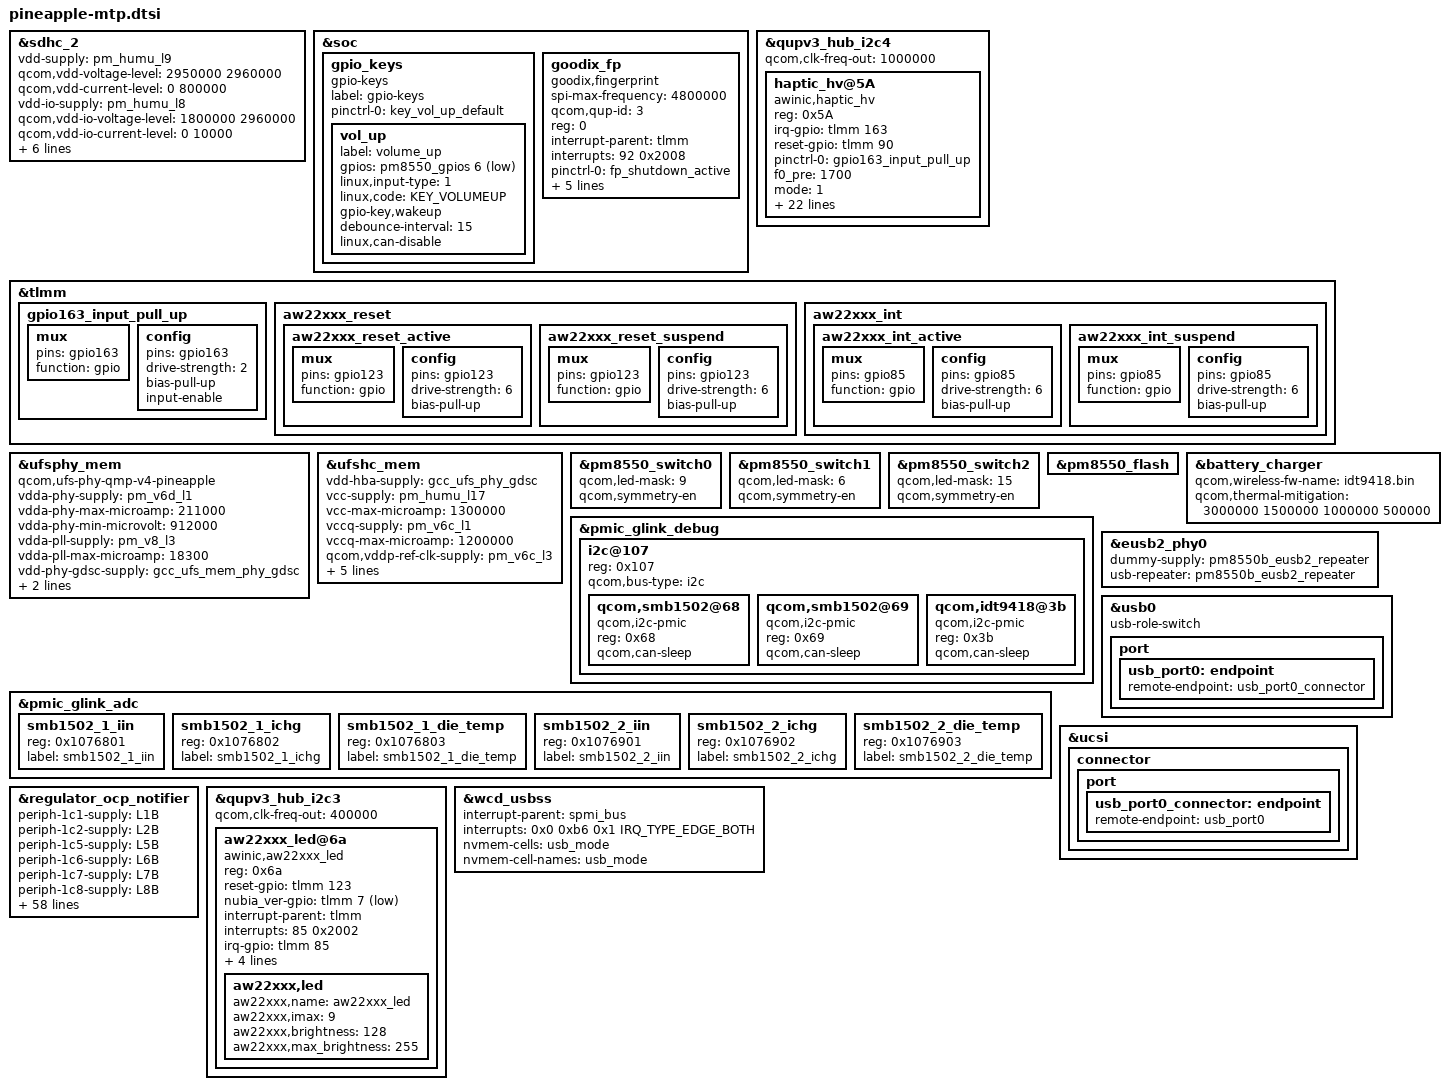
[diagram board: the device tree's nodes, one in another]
#include <dt-bindings/gpio/gpio.h>
#include <dt-bindings/input/input.h>
#include <dt-bindings/clock/qcom,gcc-pineapple.h>
#include "pineapple-pmic-overlay.dtsi"
#include "pineapple-thermal-overlay.dtsi"

&sdhc_2 {
	status = "ok";
	vdd-supply = <&pm_humu_l9>;
	qcom,vdd-voltage-level = <2950000 2960000>;
	qcom,vdd-current-level = <0 800000>;

	vdd-io-supply = <&pm_humu_l8>;
	qcom,vdd-io-voltage-level = <1800000 2960000>;
	qcom,vdd-io-current-level = <0 10000>;

	pinctrl-names = "default", "sleep";
	pinctrl-0 = <&sdc2_on>, <&sd_card_det_default>;
	pinctrl-1 = <&sdc2_off>, <&sd_card_det_default>;

	cd-gpios = <&pm8550_gpios 12 GPIO_ACTIVE_LOW>;

	resets = <&gcc GCC_SDCC2_BCR>;
	reset-names = "core_reset";

	qcom,iommu-dma = "fastmap";
	qcom,uses_level_shifter;
};

&soc {
	gpio_keys {
		compatible = "gpio-keys";
		label = "gpio-keys";

		pinctrl-names = "default";
		pinctrl-0 = <&key_vol_up_default>;

		vol_up {
			label = "volume_up";
			gpios = <&pm8550_gpios 6 GPIO_ACTIVE_LOW>;
			linux,input-type = <1>;
			linux,code = <KEY_VOLUMEUP>;
			gpio-key,wakeup;
			debounce-interval = <15>;
			linux,can-disable;
		};
	};

	goodix_fp {
		status = "ok";
		compatible = "goodix,fingerprint";
		spi-max-frequency = <4800000>;
		qcom,qup-id = <3>;
		reg = <0>;

		interrupt-parent = <&tlmm>;
		interrupts = <92 0x2008>;
		pinctrl-names = "goodix_active", "goodix_suspend", "pwr_active";
		pinctrl-0 = <&fp_shutdown_active>;
		pinctrl-1 = <&fp_shutdown_suspend>;
		pinctrl-2 = <&goodix_pwr_active>;

		fp-gpio-reset = <&tlmm 89 0x0>;
		fp-gpio-irq = <&tlmm 92 0x2008>;
		goodix,gpio_pwr = <&tlmm 93 0x1>;
		interrupt-names = "goodix_wake_up";
	};
};

/* add zte haptic start */
&qupv3_hub_i2c4 {
	status = "ok";
	qcom,clk-freq-out = <1000000>;
	haptic_hv@5A {
		compatible = "awinic,haptic_hv";
		reg = <0x5A>;
		irq-gpio = <&tlmm 163 0>;
		reset-gpio = <&tlmm 90 0>;
		pinctrl-names = "irq_active";
		pinctrl-0 = <&gpio163_input_pull_up>;
		f0_pre = < 1700 >;
		mode = /bits/ 8 < 1 >;
		f0_cali_percent = /bits/ 8 < 7 >;
/******************************aw8692x*******************************/
		aw8692x_max_bst_vol = /bits/ 8 < 0x7F >;
		aw8692x_cont_drv1_lvl = /bits/ 8 < 0x7F >;
		aw8692x_cont_drv2_lvl = /bits/ 8 < 0x50 >;
		aw8692x_cont_drv1_time = /bits/ 8 < 0x04 >;
		aw8692x_cont_drv2_time = /bits/ 8 < 0x06 >;
		aw8692x_cont_drv_width = /bits/ 8 < 0x6A >;
		aw8692x_cont_wait_num = /bits/ 8 < 0x06 >;
		aw8692x_cont_brk_time = /bits/ 8 < 0 >;
		aw8692x_cont_track_margin = /bits/ 8 < 0x0C >;
		aw8692x_brk_bst_md = /bits/ 8 < 0 >;
		aw8692x_cont_tset = /bits/ 8 < 0x06 >;
		aw8692x_cont_bemf_set = /bits/ 8 < 0x02 >;
		aw8692x_cont_bst_brk_gain = /bits/ 8 < 0x05 >;
		aw8692x_cont_brk_gain = /bits/ 8 < 0x08 >;
		aw8692x_duration_time = /bits/ 8 < 20 30 60 >;
		aw8692x_d2s_gain = /bits/ 8 < 0x04 >;
		aw8692x_trig_config = /bits/ 8 < 0 0 0 1 0 2 0 0
						 0 0 0 1 0 2 0 0
						 0 0 0 1 0 2 0 0 >;
		aw8692x_bst_vol_default = /bits/ 8 < 0x50 >;
		aw8692x_bst_vol_ram = /bits/ 8 < 0x50 >;
		aw8692x_bst_vol_rtp = /bits/ 8 < 0x50 >;
		/* aw8692x_is_enabled_auto_bst; */
		/* aw8692x_is_enabled_one_wire; */
	};
};
&tlmm {
	gpio163_input_pull_up: gpio163_input_pull_up {
		mux {
			 pins = "gpio163";
			 function = "gpio";
		};

		config {
			pins = "gpio163";
			drive-strength = <2>;
			bias-pull-up;
			input-enable;
		};
	};
};

&ufsphy_mem {
	compatible = "qcom,ufs-phy-qmp-v4-pineapple";

	/* VDDA_UFS_CORE */
	vdda-phy-supply = <&pm_v6d_l1>;
	vdda-phy-max-microamp = <211000>;
	/*
	 * Platforms supporting Gear 5 && Rate B require a different
	 * voltage supply. Check the Power Grid document.
	 */
	vdda-phy-min-microvolt = <912000>;

	/* VDDA_UFS_0_1P2 */
	vdda-pll-supply = <&pm_v8_l3>;
	vdda-pll-max-microamp = <18300>;

	/* Phy GDSC for VDD_MX, always on */
	vdd-phy-gdsc-supply = <&gcc_ufs_mem_phy_gdsc>;

	/* Qref power supply, Refer Qref diagram */
	vdda-qref-supply = <&pm_v8_l1>;
	vdda-qref-max-microamp = <64500>;

	status = "ok";
};

&ufshc_mem {
	vdd-hba-supply = <&gcc_ufs_phy_gdsc>;

	vcc-supply = <&pm_humu_l17>;
	vcc-max-microamp = <1300000>;

	vccq-supply = <&pm_v6c_l1>;
	vccq-max-microamp = <1200000>;

	/* VDD_PX10 is voted for the ufs_reset_n */
	qcom,vddp-ref-clk-supply = <&pm_v6c_l3>;
	qcom,vddp-ref-clk-max-microamp = <100>;

	qcom,vccq-parent-supply = <&pm_v6c_s1>;
	qcom,vccq-parent-max-microamp = <210000>;

	reset-gpios = <&tlmm 210 GPIO_ACTIVE_LOW>;
	resets = <&gcc GCC_UFS_PHY_BCR>;
	reset-names = "rst";

	status = "ok";
};

&pm8550_switch0 {
	qcom,led-mask = <9>; /* Channels 1 & 4 */
	qcom,symmetry-en;
};

&pm8550_switch1 {
	qcom,led-mask = <6>; /* Channels 2 & 3 */
	qcom,symmetry-en;
};

&pm8550_switch2 {
	qcom,led-mask = <15>; /* All Channels */
	qcom,symmetry-en;
};

&pm8550_flash {
	status = "ok";
};

&battery_charger {
	qcom,wireless-fw-name = "idt9418.bin";
	qcom,thermal-mitigation = <3000000 1500000 1000000 500000>;
	#cooling-cells = <2>;
};

&pmic_glink_debug {
	i2c@107 {
		reg = <0x107>; /* I2C instance 7 in ADSP for SE6 */
		#address-cells = <1>;
		#size-cells = <0>;
		qcom,bus-type = "i2c";

		qcom,smb1502@68 {
			compatible = "qcom,i2c-pmic";
			reg = <0x68>;
			qcom,can-sleep;
		};

		qcom,smb1502@69 {
			compatible = "qcom,i2c-pmic";
			reg = <0x69>;
			qcom,can-sleep;
		};

		qcom,idt9418@3b {
			compatible = "qcom,i2c-pmic";
			reg = <0x3b>;
			qcom,can-sleep;
		};
	};
};

&pmic_glink_adc {
	status = "ok";

	smb1502_1_iin {
		reg = <0x1076801>;
		label = "smb1502_1_iin";
	};

	smb1502_1_ichg {
		reg = <0x1076802>;
		label = "smb1502_1_ichg";
	};

	smb1502_1_die_temp {
		reg = <0x1076803>;
		label = "smb1502_1_die_temp";
	};

	smb1502_2_iin {
		reg = <0x1076901>;
		label = "smb1502_2_iin";
	};

	smb1502_2_ichg {
		reg = <0x1076902>;
		label = "smb1502_2_ichg";
	};

	smb1502_2_die_temp {
		reg = <0x1076903>;
		label = "smb1502_2_die_temp";
	};
};

&eusb2_phy0 {
	dummy-supply = <&pm8550b_eusb2_repeater>;
	usb-repeater = <&pm8550b_eusb2_repeater>;
};

&usb0 {
	usb-role-switch;
	port {
		usb_port0: endpoint {
			remote-endpoint = <&usb_port0_connector>;
		};
	};
};

&ucsi {
	connector {
		port {
			usb_port0_connector: endpoint {
				remote-endpoint = <&usb_port0>;
			};
		};
	};
};

&regulator_ocp_notifier {
	periph-1c1-supply = <&L1B>;
	periph-1c2-supply = <&L2B>;
	periph-1c5-supply = <&L5B>;
	periph-1c6-supply = <&L6B>;
	periph-1c7-supply = <&L7B>;
	periph-1c8-supply = <&L8B>;
	periph-1c9-supply = <&L9B>;
	periph-1ca-supply = <&L10B>;
	periph-1cb-supply = <&L11B>;
	periph-1cc-supply = <&L12B>;
	periph-1cd-supply = <&L13B>;
	periph-1ce-supply = <&L14B>;
	periph-1cf-supply = <&L15B>;
	periph-1d0-supply = <&L16B>;
	periph-1d1-supply = <&L17B>;
	periph-1e4-supply = <&BOB1>;
	periph-1e6-supply = <&BOB2>;
	periph-29b-supply = <&S1C>;
	periph-29e-supply = <&S2C>;
	periph-2a1-supply = <&S3C>;
	periph-2a4-supply = <&S4C>;
	periph-2a7-supply = <&S5C>;
	periph-2aa-supply = <&S6C>;
	periph-2c1-supply = <&L1C>;
	periph-2c2-supply = <&L2C>;
	periph-2c3-supply = <&L3C>;
	periph-3a1-supply = <&S3D_LEVEL>;
	periph-3a4-supply = <&S4D_LEVEL>;
	periph-3a7-supply = <&S5D_LEVEL>;
	periph-3c1-supply = <&L1D>;
	periph-3c2-supply = <&L2D_LEVEL>;
	periph-3c3-supply = <&L3D>;
	periph-4c2-supply = <&L2E>;
	periph-4c3-supply = <&L3E>;
	periph-69b-supply = <&S1G_LEVEL>;
	periph-6a1-supply = <&S3G>;
	periph-6a4-supply = <&S4G_LEVEL>;
	periph-6a7-supply = <&S5G_LEVEL>;
	periph-6c1-supply = <&L1G>;
	periph-6c2-supply = <&L2G>;
	periph-6c3-supply = <&L3G>;
	periph-89b-supply = <&S1I_LEVEL>;
	periph-8a1-supply = <&S3I_LEVEL>;
	periph-8a4-supply = <&S4I>;
	periph-8a7-supply = <&S5I>;
	periph-8aa-supply = <&S6I_LEVEL>;
	periph-8b0-supply = <&S8I_LEVEL>;
	periph-8c1-supply = <&L1I>;
	periph-8c2-supply = <&L2I>;
	periph-8c3-supply = <&L3I>;
	periph-ac1-supply = <&L1K>;
	periph-ac2-supply = <&L2K>;
	periph-ac3-supply = <&L3K>;
	periph-ac4-supply = <&L4K>;
	periph-ac5-supply = <&L5K>;
	periph-ac6-supply = <&L6K>;
	periph-ac7-supply = <&L7K>;
	periph-c40-supply = <&L1M>;
	periph-c41-supply = <&L2M>;
	periph-c42-supply = <&L3M>;
	periph-c43-supply = <&L4M>;
	periph-c44-supply = <&L5M>;
	periph-c45-supply = <&L6M>;
	periph-c46-supply = <&L7M>;
};

/*aw22xxx_led start*/
&qupv3_hub_i2c3 {
  #address-cells = <1>;
  #size-cells = <0>;
  status = "okay";
  qcom,clk-freq-out = <400000>;
	aw22xxx_led@6a {
		status = "okay";
		compatible = "awinic,aw22xxx_led";
		reg = <0x6a>;
		reset-gpio = <&tlmm 123 0x0>;
		nubia_ver-gpio = <&tlmm 7 1>;
		interrupt-parent = <&tlmm>;
		interrupts = <85 0x2002>;
		irq-gpio = <&tlmm 85 0x2002>;
		pinctrl-names = "aw22xxx_led_default", "aw22xxx_led_sleep";
		pinctrl-0 = <&aw22xxx_int_active &aw22xxx_reset_active>;
		pinctrl-1 = <&aw22xxx_int_suspend &aw22xxx_reset_suspend>;
		aw22xxx,led {
			aw22xxx,name = "aw22xxx_led";
			aw22xxx,imax = <9>;
			aw22xxx,brightness = <128>;
			aw22xxx,max_brightness = <255>;
		};
	};
};

&tlmm{
		aw22xxx_reset {
			aw22xxx_reset_active: aw22xxx_reset_active {
				mux {
					pins = "gpio123";
					function = "gpio";
				};
				config {
					pins = "gpio123";
					drive-strength = <6>;
					bias-pull-up;
				};
			};

			aw22xxx_reset_suspend: aw22xxx_reset_suspend {
				mux {
					pins = "gpio123";
					function = "gpio";
				};
				config {
					pins = "gpio123";
					drive-strength = <6>;
					bias-pull-up;
				};
			};
		};

		aw22xxx_int {
			aw22xxx_int_active: aw22xxx_int_active {
				mux {
					pins = "gpio85";
					function = "gpio";
				};
				config {
					pins = "gpio85";
					drive-strength = <6>;
					bias-pull-up;
				};
			};
			aw22xxx_int_suspend: aw22xxx_int_suspend {
				mux {
					pins = "gpio85";
					function = "gpio";
				};
				config {
					pins = "gpio85";
					drive-strength = <6>;
					bias-pull-up;
				};
			};
		};
};
/*aw22xxx_led end*/

&wcd_usbss {
	interrupt-parent = <&spmi_bus>;
	interrupts = <0x0 0xb6 0x1 IRQ_TYPE_EDGE_BOTH>;
	interrupt-names = "usb_wcd";
	nvmem-cells = <&usb_mode>;
	nvmem-cell-names = "usb_mode";
};
